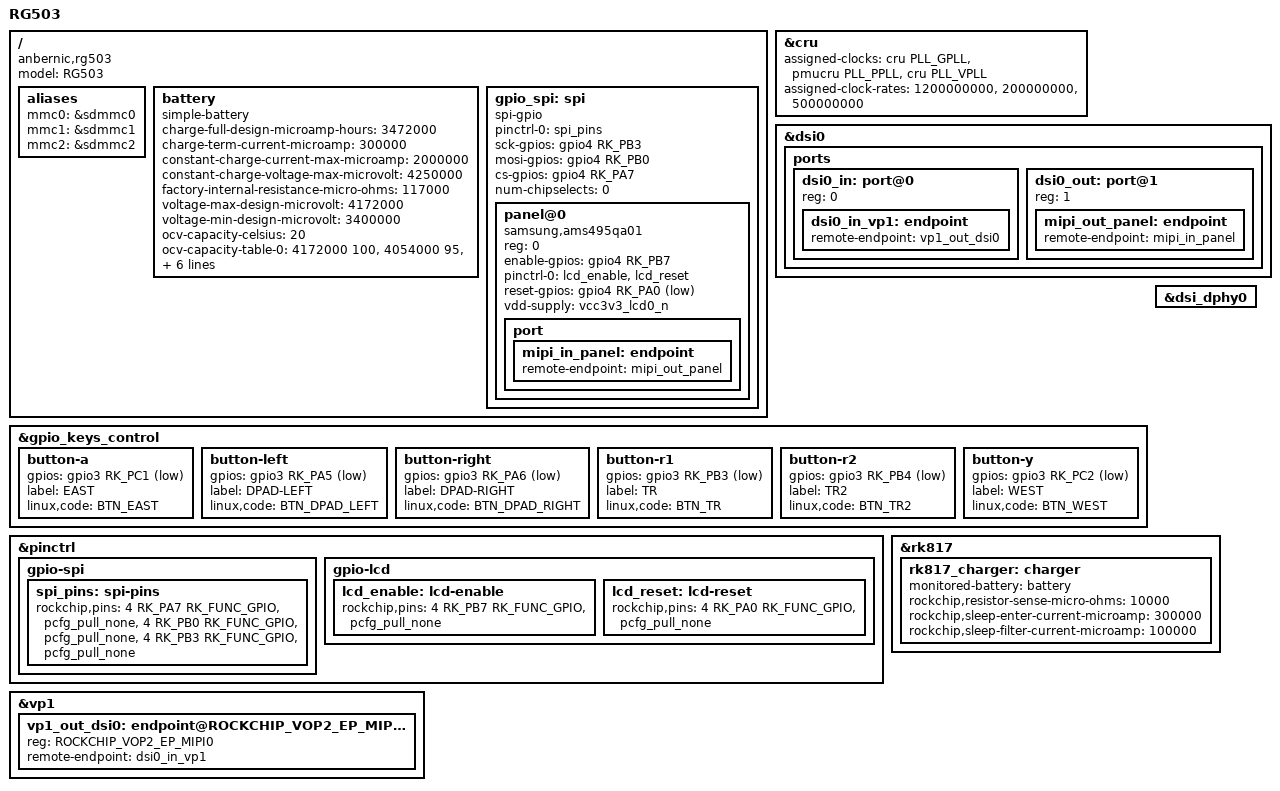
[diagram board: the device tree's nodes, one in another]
// SPDX-License-Identifier: (GPL-2.0+ OR MIT)

/dts-v1/;

#include <dt-bindings/gpio/gpio.h>
#include <dt-bindings/input/linux-event-codes.h>
#include <dt-bindings/pinctrl/rockchip.h>
#include "rk3566-anbernic-rgxx3.dtsi"

/ {
	model = "RG503";
	compatible = "anbernic,rg503", "rockchip,rk3566";

	aliases {
		mmc0 = &sdmmc0;
		mmc1 = &sdmmc1;
		mmc2 = &sdmmc2;
	};

	battery: battery {
		compatible = "simple-battery";
		charge-full-design-microamp-hours = <3472000>;
		charge-term-current-microamp = <300000>;
		constant-charge-current-max-microamp = <2000000>;
		constant-charge-voltage-max-microvolt = <4250000>;
		factory-internal-resistance-micro-ohms = <117000>;
		voltage-max-design-microvolt = <4172000>;
		voltage-min-design-microvolt = <3400000>;

		ocv-capacity-celsius = <20>;
		ocv-capacity-table-0 =  <4172000 100>, <4054000 95>, <3984000 90>, <3926000 85>,
					<3874000 80>, <3826000 75>, <3783000 70>, <3746000 65>,
					<3714000 60>, <3683000 55>, <3650000 50>, <3628000 45>,
					<3612000 40>, <3600000 35>, <3587000 30>, <3571000 25>,
					<3552000 20>, <3525000 15>, <3492000 10>, <3446000 5>,
					<3400000 0>;
	};

	gpio_spi: spi {
		compatible = "spi-gpio";
		pinctrl-names = "default";
		pinctrl-0 = <&spi_pins>;
		#address-cells = <1>;
		#size-cells = <0>;

		sck-gpios = <&gpio4 RK_PB3 GPIO_ACTIVE_HIGH>;
		mosi-gpios = <&gpio4 RK_PB0 GPIO_ACTIVE_HIGH>;
		cs-gpios = <&gpio4 RK_PA7 GPIO_ACTIVE_HIGH>;
		num-chipselects = <0>;

		panel@0 {
			compatible = "samsung,ams495qa01";
			reg = <0>;
			enable-gpios = <&gpio4 RK_PB7 GPIO_ACTIVE_HIGH>;
			pinctrl-names = "default";
			pinctrl-0 = <&lcd_enable>, <&lcd_reset>;
			reset-gpios = <&gpio4 RK_PA0 GPIO_ACTIVE_LOW>;
			vdd-supply = <&vcc3v3_lcd0_n>;

			port {
				mipi_in_panel: endpoint {
					remote-endpoint = <&mipi_out_panel>;
				};
			};
		};
	};
};

&cru {
	assigned-clocks = <&cru PLL_GPLL>, <&pmucru PLL_PPLL>, <&cru PLL_VPLL>;
	assigned-clock-rates = <1200000000>, <200000000>, <500000000>;
};

&dsi0 {
	status = "okay";

	ports {
		dsi0_in: port@0 {
			reg = <0>;

			dsi0_in_vp1: endpoint {
				remote-endpoint = <&vp1_out_dsi0>;
			};
		};

		dsi0_out: port@1 {
			reg = <1>;

			mipi_out_panel: endpoint {
				remote-endpoint = <&mipi_in_panel>;
			};
		};
	};
};

&gpio_keys_control {
	button-a {
		gpios = <&gpio3 RK_PC1 GPIO_ACTIVE_LOW>;
		label = "EAST";
		linux,code = <BTN_EAST>;
	};

	button-left {
		gpios = <&gpio3 RK_PA5 GPIO_ACTIVE_LOW>;
		label = "DPAD-LEFT";
		linux,code = <BTN_DPAD_LEFT>;
	};

	button-right {
		gpios = <&gpio3 RK_PA6 GPIO_ACTIVE_LOW>;
		label = "DPAD-RIGHT";
		linux,code = <BTN_DPAD_RIGHT>;
	};

	button-r1 {
		gpios = <&gpio3 RK_PB3 GPIO_ACTIVE_LOW>;
		label = "TR";
		linux,code = <BTN_TR>;
	};

	button-r2 {
		gpios = <&gpio3 RK_PB4 GPIO_ACTIVE_LOW>;
		label = "TR2";
		linux,code = <BTN_TR2>;
	};

	button-right {
		gpios = <&gpio3 RK_PA6 GPIO_ACTIVE_LOW>;
		label = "DPAD-RIGHT";
		linux,code = <BTN_DPAD_RIGHT>;
	};

	button-y {
		gpios = <&gpio3 RK_PC2 GPIO_ACTIVE_LOW>;
		label = "WEST";
		linux,code = <BTN_WEST>;
	};
};

&dsi_dphy0 {
	status = "okay";
};

&pinctrl {
	gpio-spi {
		spi_pins: spi-pins {
			rockchip,pins =
				<4 RK_PA7 RK_FUNC_GPIO &pcfg_pull_none>,
				<4 RK_PB0 RK_FUNC_GPIO &pcfg_pull_none>,
				<4 RK_PB3 RK_FUNC_GPIO &pcfg_pull_none>;
		};
	};

	gpio-lcd {
		lcd_enable: lcd-enable {
			rockchip,pins =
				<4 RK_PB7 RK_FUNC_GPIO &pcfg_pull_none>;
		};

		lcd_reset: lcd-reset {
			rockchip,pins =
				<4 RK_PA0 RK_FUNC_GPIO &pcfg_pull_none>;
		};
	};
};

&rk817 {
	rk817_charger: charger {
		monitored-battery = <&battery>;
		rockchip,resistor-sense-micro-ohms = <10000>;
		rockchip,sleep-enter-current-microamp = <300000>;
		rockchip,sleep-filter-current-microamp = <100000>;
	};
};

&vp1 {
	vp1_out_dsi0: endpoint@ROCKCHIP_VOP2_EP_MIPI0 {
		reg = <ROCKCHIP_VOP2_EP_MIPI0>;
		remote-endpoint = <&dsi0_in_vp1>;
	};
};
